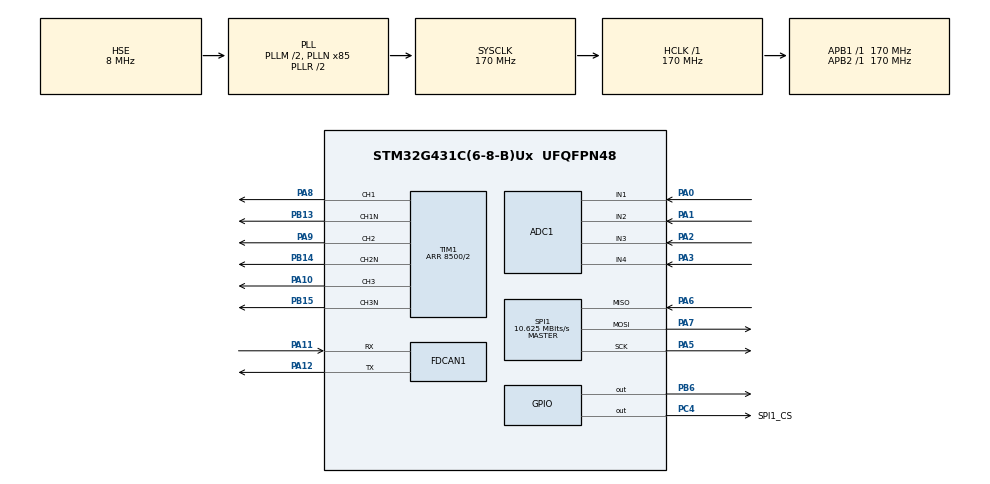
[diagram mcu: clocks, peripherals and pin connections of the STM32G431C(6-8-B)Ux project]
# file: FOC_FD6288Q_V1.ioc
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ADC1.ContinuousConvMode=ENABLE
ADC1.EnableInjectedConversion=ENABLE
ADC1.EnableRegularConversion=DISABLE
ADC1.ExternalTrigInjecConv=ADC_EXTERNALTRIGINJEC_T1_TRGO2
ADC1.ExternalTrigInjecConvEdge=ADC_EXTERNALTRIGINJECCONV_EDGE_FALLING
ADC1.InjNumberOfConversion=4
ADC1.InjectedChannel-1\#ChannelInjectedConversion=ADC_CHANNEL_1
ADC1.InjectedChannel-2\#ChannelInjectedConversion=ADC_CHANNEL_2
ADC1.InjectedChannel-3\#ChannelInjectedConversion=ADC_CHANNEL_3
ADC1.InjectedChannel-4\#ChannelInjectedConversion=ADC_CHANNEL_4
ADC1.InjectedOffsetNumber-1\#ChannelInjectedConversion=ADC_OFFSET_NONE
ADC1.InjectedOffsetNumber-2\#ChannelInjectedConversion=ADC_OFFSET_NONE
ADC1.InjectedOffsetNumber-3\#ChannelInjectedConversion=ADC_OFFSET_NONE
ADC1.InjectedOffsetNumber-4\#ChannelInjectedConversion=ADC_OFFSET_NONE
ADC1.InjectedRank-1\#ChannelInjectedConversion=1
ADC1.InjectedRank-2\#ChannelInjectedConversion=2
ADC1.InjectedRank-3\#ChannelInjectedConversion=3
ADC1.InjectedRank-4\#ChannelInjectedConversion=4
ADC1.InjectedSamplingTime-1\#ChannelInjectedConversion=ADC_SAMPLETIME_2CYCLES_5
ADC1.InjectedSamplingTime-2\#ChannelInjectedConversion=ADC_SAMPLETIME_2CYCLES_5
ADC1.InjectedSamplingTime-3\#ChannelInjectedConversion=ADC_SAMPLETIME_2CYCLES_5
ADC1.InjectedSamplingTime-4\#ChannelInjectedConversion=ADC_SAMPLETIME_2CYCLES_5
ADC1.Rank1_Channel=ADC_CHANNEL_1
ADC1.Rank2_Channel=ADC_CHANNEL_2
ADC1.Rank3_Channel=ADC_CHANNEL_3
ADC1.Rank4_Channel=ADC_CHANNEL_4
ADC1.master=1
FDCAN1.AutoRetransmission=ENABLE
FDCAN1.CalculateBaudRateNominal=625000
FDCAN1.CalculateTimeBitNominal=1600
FDCAN1.CalculateTimeQuantumNominal=100.0
FDCAN1.ClockDivider=FDCAN_CLOCK_DIV1
FDCAN1.DataPrescaler=17
FDCAN1.DataTimeSeg1=13
FDCAN1.DataTimeSeg2=2
FDCAN1.FrameFormat=FDCAN_FRAME_CLASSIC
FDCAN1.Mode=FDCAN_MODE_NORMAL
FDCAN1.NominalPrescaler=17
FDCAN1.NominalTimeSeg1=13
FDCAN1.StdFiltersNbr=1
Mcu.Family=STM32G4
Mcu.Name=STM32G431C(6-8-B)Ux
Mcu.Package=UFQFPN48
NVIC.ADC1_2_IRQn=true\:0\:0\:false\:false\:true\:true\:true\:true
NVIC.FDCAN1_IT0_IRQn=true\:0\:0\:false\:false\:true\:true\:true\:true
NVIC.PriorityGroup=NVIC_PRIORITYGROUP_4
NVIC.TIM7_IRQn=true\:0\:0\:false\:false\:true\:true\:true\:true
PA0.Mode=IN1-Single-Ended
PA0.Signal=ADC1_IN1
PA1.Mode=IN2-Single-Ended
PA1.Signal=ADC1_IN2
PA10.GPIO_Speed=GPIO_SPEED_FREQ_HIGH
PA10.Signal=S_TIM1_CH3
PA11.Mode=FDCAN_Activate
PA11.Signal=FDCAN1_RX
PA12.Mode=FDCAN_Activate
PA12.Signal=FDCAN1_TX
PA13.Mode=Serial_Wire
PA13.Signal=SYS_JTMS-SWDIO
PA14.Mode=Serial_Wire
PA14.Signal=SYS_JTCK-SWCLK
PA2.Mode=IN3-Single-Ended
PA2.Signal=ADC1_IN3
PA3.Mode=IN4-Single-Ended
PA3.Signal=ADC1_IN4
PA5.Mode=Full_Duplex_Master
PA5.Signal=SPI1_SCK
PA6.GPIO_Speed=GPIO_SPEED_FREQ_VERY_HIGH
PA6.Mode=Full_Duplex_Master
PA6.Signal=SPI1_MISO
PA7.Mode=Full_Duplex_Master
PA7.Signal=SPI1_MOSI
PA8.GPIO_Speed=GPIO_SPEED_FREQ_HIGH
PA8.Signal=S_TIM1_CH1
PA9.GPIO_Speed=GPIO_SPEED_FREQ_HIGH
PA9.Signal=S_TIM1_CH2
PB13.GPIO_Speed=GPIO_SPEED_FREQ_HIGH
PB13.Mode=PWM Generation1 CH1 CH1N
PB13.Signal=TIM1_CH1N
PB14.GPIO_Speed=GPIO_SPEED_FREQ_HIGH
PB14.Mode=PWM Generation2 CH2 CH2N
PB14.Signal=TIM1_CH2N
PB15.GPIO_Speed=GPIO_SPEED_FREQ_HIGH
PB15.Mode=PWM Generation3 CH3 CH3N
PB15.Signal=TIM1_CH3N
PB6.Signal=GPIO_Output
PC4.GPIO_Label=SPI1_CS
PC4.GPIO_Speed=GPIO_SPEED_FREQ_VERY_HIGH
PC4.Signal=GPIO_Output
PF0-OSC_IN.Mode=HSE-External-Oscillator
PF0-OSC_IN.Signal=RCC_OSC_IN
PF1-OSC_OUT.Mode=HSE-External-Oscillator
PF1-OSC_OUT.Signal=RCC_OSC_OUT
ProjectManager.HeapSize=0x200
ProjectManager.StackSize=0x400
ProjectManager.TargetToolchain=MDK-ARM V5.32
RCC.ADC12Freq_Value=170000000
RCC.AHBFreq_Value=170000000
RCC.APB1Freq_Value=170000000
RCC.APB1TimFreq_Value=170000000
RCC.APB2Freq_Value=170000000
RCC.APB2TimFreq_Value=170000000
RCC.CortexFreq_Value=170000000
RCC.EXTERNAL_CLOCK_VALUE=12288000
RCC.HCLKFreq_Value=170000000
RCC.HSE_VALUE=8000000
RCC.HSI48_VALUE=48000000
RCC.HSI_VALUE=16000000
RCC.LSE_VALUE=32768
RCC.PLLM=RCC_PLLM_DIV2
RCC.PLLN=85
RCC.PLLSourceVirtual=RCC_PLLSOURCE_HSE
RCC.SYSCLKFreq_VALUE=170000000
RCC.SYSCLKSource=RCC_SYSCLKSOURCE_PLLCLK
RCC.USBFreq_Value=170000000
RCC.VCOOutputFreq_Value=340000000
SH.S_TIM1_CH1.0=TIM1_CH1,PWM Generation1 CH1 CH1N
SH.S_TIM1_CH2.0=TIM1_CH2,PWM Generation2 CH2 CH2N
SH.S_TIM1_CH3.0=TIM1_CH3,PWM Generation3 CH3 CH3N
SPI1.BaudRatePrescaler=SPI_BAUDRATEPRESCALER_16
SPI1.CLKPhase=SPI_PHASE_2EDGE
SPI1.CalculateBaudRate=10.625 MBits/s
SPI1.DataSize=SPI_DATASIZE_8BIT
SPI1.Direction=SPI_DIRECTION_2LINES
SPI1.Mode=SPI_MODE_MASTER
SPI1.VirtualType=VM_MASTER
STMicroelectronics.X-CUBE-ALGOBUILD.1.4.0.LibraryCcDSPOoLibraryJjDSPOoLibrary=true
TIM1.AutoReloadPreload=TIM_AUTORELOAD_PRELOAD_ENABLE
TIM1.AutomaticOutput=TIM_AUTOMATICOUTPUT_ENABLE
TIM1.Channel-PWM\ Generation1\ CH1\ CH1N=TIM_CHANNEL_1
TIM1.Channel-PWM\ Generation2\ CH2\ CH2N=TIM_CHANNEL_2
TIM1.Channel-PWM\ Generation3\ CH3\ CH3N=TIM_CHANNEL_3
TIM1.Channel-PWM\ Generation4\ No\ Output=TIM_CHANNEL_4
TIM1.CounterMode=TIM_COUNTERMODE_CENTERALIGNED1
TIM1.LockLevel=TIM_LOCKLEVEL_1
TIM1.OCMode_PWM-PWM\ Generation1\ CH1\ CH1N=TIM_OCMODE_PWM2
TIM1.OCMode_PWM-PWM\ Generation2\ CH2\ CH2N=TIM_OCMODE_PWM2
TIM1.OCMode_PWM-PWM\ Generation3\ CH3\ CH3N=TIM_OCMODE_PWM2
TIM1.OCMode_PWM-PWM\ Generation4\ No\ Output=TIM_OCMODE_PWM1
TIM1.OffStateIDLEMode=TIM_OSSI_ENABLE
TIM1.OffStateRunMode=TIM_OSSR_ENABLE
TIM1.PeriodNoDither=8500/2
TIM1.PulseNoDither_1=2125
TIM1.PulseNoDither_2=2125
TIM1.PulseNoDither_3=2125
TIM1.PulseNoDither_4=200
TIM1.RepetitionCounter=1
TIM1.TIM_MasterOutputTrigger=TIM_TRGO_UPDATE
TIM1.TIM_MasterOutputTrigger2=TIM_TRGO2_OC4REF_RISINGFALLING
TIM7.AutoReloadPreload=TIM_AUTORELOAD_PRELOAD_DISABLE
TIM7.PeriodNoDither=2500-1
TIM7.Prescaler=17-1
VP_CORDIC_VS_CORDIC.Mode=CORDIC_Activate
VP_STMicroelectronics.X-CUBE-ALGOBUILD_VS_DSPOoLibraryJjLibrary_1.4.0_1.4.0.Mode=DSPOoLibraryJjLibrary
VP_SYS_VS_DBSignals.Mode=DisableDeadBatterySignals
VP_TIM1_VS_ClockSourceINT.Mode=Internal
VP_TIM1_VS_no_output4.Mode=PWM Generation4 No Output
VP_TIM7_VS_ClockSourceINT.Mode=Enable_Timer
board=custom

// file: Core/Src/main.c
/* USER CODE BEGIN Header */
/**
  ******************************************************************************
  * @file           : main.c
  * @brief          : Main program body
  ******************************************************************************
  * @attention
  *
  * Copyright (c) 2025 STMicroelectronics.
  * All rights reserved.
  *
  * This software is licensed under terms that can be found in the LICENSE file
  * in the root directory of this software component.
  * If no LICENSE file comes with this software, it is provided AS-IS.
  *
  ******************************************************************************
  */
/* USER CODE END Header */
#include "main.h"
#include "adc.h"
#include "cordic.h"
#include "fdcan.h"
#include "spi.h"
#include "tim.h"
#include "gpio.h"

void SystemClock_Config(void);

/* USER CODE BEGIN 0 */

#include "ALL_H.h"
#include "MT6701.h"
#include "PMSM_MC_2025a.h"

uint16_t ADC1InjectDate[4];     //注入组采样数组

float Fir_Output[4]={0};        //Fir滤波器滤波后的值

AdcValue adcvalue;              //ADC采样变量
AllFlag allflag;                //标志位变量
Encoder_Struct encoder_str;     //编码器结构体
SVPWM_Struct svpwm_str;         //svpwm结构体
PID pid_m1;                     //PID参数结构体
CANFD_Message CanFD_Message;    //CAN通信消息结构体

/* USER CODE END 0 */

int main(void)
{

  /* MCU Configuration--------------------------------------------------------*/

  /* Reset of all peripherals, Initializes the Flash interface and the Systick. */
  HAL_Init();

  /* Configure the system clock */
  SystemClock_Config();

  /* Initialize all configured peripherals */
  MX_GPIO_Init();
  MX_ADC1_Init();
  MX_SPI1_Init();
  MX_TIM1_Init();
  MX_CORDIC_Init();
  MX_FDCAN1_Init();
  MX_TIM7_Init();
  /* USER CODE BEGIN 2 */

  HAL_Delay(1000);

	PMSM_MC_2025a_initialize();

	//中断初始化
	Enable_IT();

  /* USER CODE END 2 */

  /* Infinite loop */
  while (1)
  {

    /* USER CODE BEGIN 3 */

//	  encoder_str.Encoder = MT6701_ReadRaw();//10us
//	allflag.CANFD_Tx_flag=CANFD_Send(0x10,3,encoder_str.Encoder_raw,0,pid_m1.Iq_current);

//	  printf("raw:%d\r\n",raw);
  }
  /* USER CODE END 3 */
}

void SystemClock_Config(void)
{
  RCC_OscInitTypeDef RCC_OscInitStruct = {0};
  RCC_ClkInitTypeDef RCC_ClkInitStruct = {0};

  /** Configure the main internal regulator output voltage
  */
  HAL_PWREx_ControlVoltageScaling(PWR_REGULATOR_VOLTAGE_SCALE1_BOOST);

  /** Initializes the RCC Oscillators according to the specified parameters
  * in the RCC_OscInitTypeDef structure.
  */
  RCC_OscInitStruct.OscillatorType = RCC_OSCILLATORTYPE_HSE;
  RCC_OscInitStruct.HSEState = RCC_HSE_ON;
  RCC_OscInitStruct.PLL.PLLState = RCC_PLL_ON;
  RCC_OscInitStruct.PLL.PLLSource = RCC_PLLSOURCE_HSE;
  RCC_OscInitStruct.PLL.PLLM = RCC_PLLM_DIV2;
  RCC_OscInitStruct.PLL.PLLN = 85;
  RCC_OscInitStruct.PLL.PLLP = RCC_PLLP_DIV2;
  RCC_OscInitStruct.PLL.PLLQ = RCC_PLLQ_DIV2;
  RCC_OscInitStruct.PLL.PLLR = RCC_PLLR_DIV2;
  if (HAL_RCC_OscConfig(&RCC_OscInitStruct) != HAL_OK)
  {
    Error_Handler();
  }

  /** Initializes the CPU, AHB and APB buses clocks
  */
  RCC_ClkInitStruct.ClockType = RCC_CLOCKTYPE_HCLK|RCC_CLOCKTYPE_SYSCLK
                              |RCC_CLOCKTYPE_PCLK1|RCC_CLOCKTYPE_PCLK2;
  RCC_ClkInitStruct.SYSCLKSource = RCC_SYSCLKSOURCE_PLLCLK;
  RCC_ClkInitStruct.AHBCLKDivider = RCC_SYSCLK_DIV1;
  RCC_ClkInitStruct.APB1CLKDivider = RCC_HCLK_DIV1;
  RCC_ClkInitStruct.APB2CLKDivider = RCC_HCLK_DIV1;

  if (HAL_RCC_ClockConfig(&RCC_ClkInitStruct, FLASH_LATENCY_4) != HAL_OK)
  {
    Error_Handler();
  }
}

void Error_Handler(void)
{
  __disable_irq();
  while (1)
  {
  }
}
